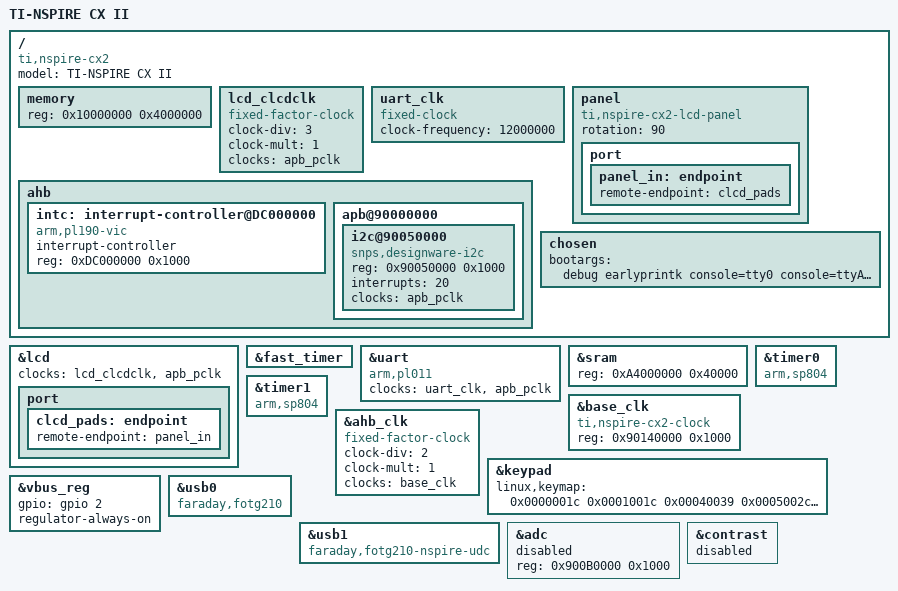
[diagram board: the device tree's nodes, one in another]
// SPDX-License-Identifier: GPL-2.0-only
/*
 *  linux/arch/arm/boot/nspire-cx2.dts
 *
 *  Copyright (C) 2013 Daniel Tang <tangrs@tangrs.id.au>
 *  Copyright (C) 2021 Fabian Vogt <fabian@ritter-vogt.de>
 */
/dts-v1/;

/include/ "nspire.dtsi"

&lcd {
	clocks = <&lcd_clcdclk>, <&apb_pclk>;
	clock-names = "clcdclk", "apb_pclk";

	port {
		clcd_pads: endpoint {
			remote-endpoint = <&panel_in>;
		};
	};
};

&fast_timer {
	/* compatible = "arm,sp804", "arm,primecell"; */
};

&uart {
	compatible = "arm,pl011", "arm,primecell";

	clocks = <&uart_clk>, <&apb_pclk>;
	clock-names = "uart_clk", "apb_pclk";
};

&sram {
	reg = <0xA4000000 0x40000>;
};

&timer0 {
	compatible = "arm,sp804", "arm,primecell";
};

&timer1 {
	compatible = "arm,sp804", "arm,primecell";
};

&base_clk {
	compatible = "ti,nspire-cx2-clock";
	reg = <0x90140000 0x1000>;
};

&ahb_clk {
	#clock-cells = <0>;
	compatible = "fixed-factor-clock";
	clock-div = <2>;
	clock-mult = <1>;
	clocks = <&base_clk>;
};

&keypad {
	linux,keymap = <
	0x0000001c 	0x0001001c 	0x00040039
	0x0005002c 	0x00060015 	0x0007000b
	0x0008000f 	0x0100002d 	0x01010011
	0x0102002f 	0x01030004 	0x01040016
	0x01050014 	0x0106001f 	0x01070002
	0x010a006a 	0x02000013 	0x02010010
	0x02020019 	0x02030007 	0x02040018
	0x02050031 	0x02060032 	0x02070005
	0x02080028 	0x0209006c 	0x03000026
	0x03010025 	0x03020024 	0x0303000a
	0x03040017 	0x03050023 	0x03060022
	0x03070008 	0x03080035 	0x03090069
	0x04000021 	0x04010012 	0x04020020
	0x0404002e 	0x04050030 	0x0406001e
	0x0407000d 	0x04080037 	0x04090067
	0x05010038 	0x0502000c 	0x0503001b
	0x05040034 	0x0505001a 	0x05060006
	0x05080027 	0x0509000e 	0x050a006f
	0x0600002b 	0x0602004e 	0x06030068
	0x06040003 	0x0605006d 	0x06060009
	0x06070001 	0x0609000f 	0x0708002a
	0x0709001d 	0x070a0033 	>;
};

&vbus_reg {
	gpio = <&gpio 2 0>;
	// A bit of a hack:
	// There are GPIOs for ID and VBus detection,
	// but there is no driver for role switching, so gpio-usb-b-connector
	// can't be used. So for now role (i.e. driver) and VBus have to be hardcoded.
	regulator-always-on;
};

&usb0 {
	compatible = "faraday,fotg210";
};

&usb1 {
	compatible = "faraday,fotg210-nspire-udc";
};

&adc {
	reg = <0x900B0000 0x1000>;
	status = "disabled";
};

&contrast {
	status = "disabled";
};

/ {
	model = "TI-NSPIRE CX II";
	compatible = "ti,nspire-cx2";

	memory {
		device_type = "memory";
		reg = <0x10000000 0x4000000>; /* 64 MB */
	};

	lcd_clcdclk: lcd_clcdclk {
		#clock-cells = <0>;
		compatible = "fixed-factor-clock";
		clock-div = <3>;
		clock-mult = <1>;
		clocks = <&apb_pclk>;
	};

	uart_clk: uart_clk {
		#clock-cells = <0>;
		compatible = "fixed-clock";
		clock-frequency = <12000000>;
	};

	ahb {
		#address-cells = <1>;
		#size-cells = <1>;

		intc: interrupt-controller@DC000000 {
			compatible = "arm,pl190-vic";
			interrupt-controller;
			reg = <0xDC000000 0x1000>;
			#interrupt-cells = <1>;
		};

		apb@90000000 {
			#address-cells = <1>;
			#size-cells = <1>;

			i2c@90050000 {
				compatible = "snps,designware-i2c";
				reg = <0x90050000 0x1000>;
				interrupts = <20>;
				clocks = <&apb_pclk>;
			};
		};
	};

	panel {
		compatible = "ti,nspire-cx2-lcd-panel";
		rotation = <90>;
		port {
			panel_in: endpoint {
				remote-endpoint = <&clcd_pads>;
			};
		};
	};
	chosen {
		bootargs = "debug earlyprintk console=tty0 console=ttyAMA0,115200n8 root=/dev/ram0";
	};
};
